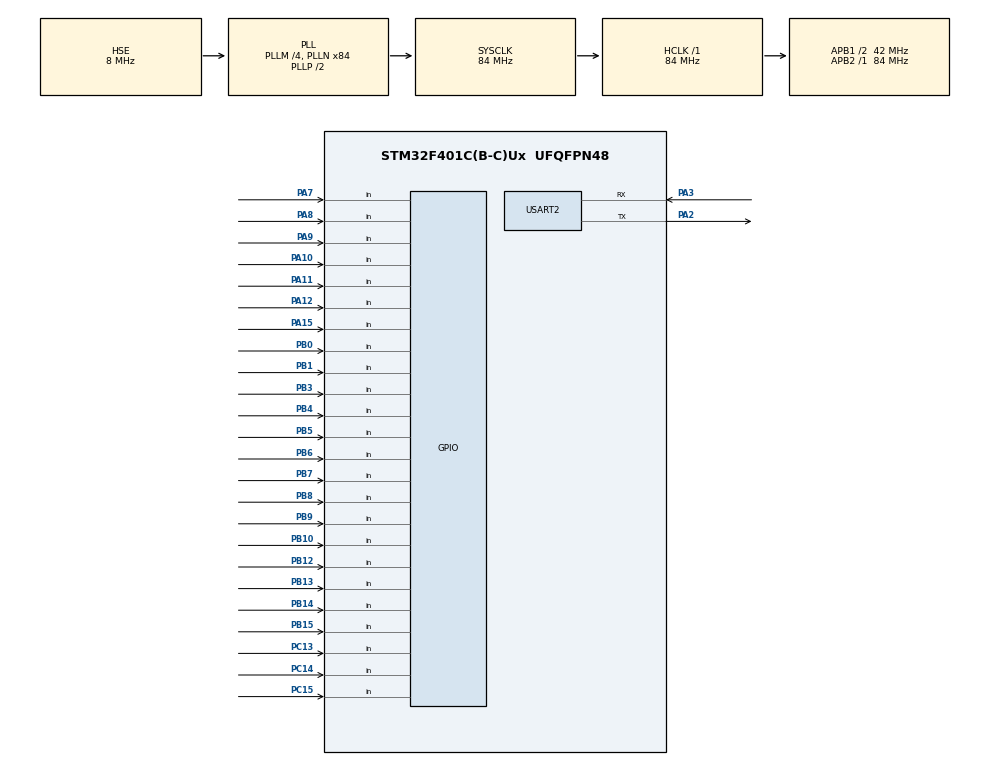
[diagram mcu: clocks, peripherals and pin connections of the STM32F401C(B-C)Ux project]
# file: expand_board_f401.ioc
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Mcu.Family=STM32F4
Mcu.Name=STM32F401C(B-C)Ux
Mcu.Package=UFQFPN48
NVIC.PriorityGroup=NVIC_PRIORITYGROUP_4
PA10.Signal=GPIO_Input
PA11.Signal=GPIO_Input
PA12.Signal=GPIO_Input
PA13.Mode=Serial_Wire
PA13.Signal=SYS_JTMS-SWDIO
PA14.Mode=Serial_Wire
PA14.Signal=SYS_JTCK-SWCLK
PA15.Signal=GPIO_Input
PA2.Mode=Asynchronous
PA2.Signal=USART2_TX
PA3.Mode=Asynchronous
PA3.Signal=USART2_RX
PA7.Signal=GPIO_Input
PA8.Signal=GPIO_Input
PA9.Signal=GPIO_Input
PB0.Signal=GPIO_Input
PB1.Signal=GPIO_Input
PB10.Signal=GPIO_Input
PB12.Signal=GPIO_Input
PB13.Signal=GPIO_Input
PB14.Signal=GPIO_Input
PB15.Signal=GPIO_Input
PB3.Signal=GPIO_Input
PB4.Signal=GPIO_Input
PB5.Signal=GPIO_Input
PB6.Signal=GPIO_Input
PB7.Signal=GPIO_Input
PB8.Signal=GPIO_Input
PB9.Signal=GPIO_Input
PC13-ANTI_TAMP.Signal=GPIO_Input
PC14-OSC32_IN.Signal=GPIO_Input
PC15-OSC32_OUT.Signal=GPIO_Input
PH0\ -\ OSC_IN.Mode=HSE-External-Oscillator
PH0\ -\ OSC_IN.Signal=RCC_OSC_IN
PH1\ -\ OSC_OUT.Mode=HSE-External-Oscillator
PH1\ -\ OSC_OUT.Signal=RCC_OSC_OUT
ProjectManager.HeapSize=0x200
ProjectManager.StackSize=0x400
ProjectManager.TargetToolchain=MDK-ARM V5.32
RCC.48MHZClocksFreq_Value=42000000
RCC.AHBFreq_Value=84000000
RCC.APB1CLKDivider=RCC_HCLK_DIV2
RCC.APB1Freq_Value=42000000
RCC.APB1TimFreq_Value=84000000
RCC.APB2Freq_Value=84000000
RCC.APB2TimFreq_Value=84000000
RCC.CortexFreq_Value=84000000
RCC.HCLKFreq_Value=84000000
RCC.HSE_VALUE=8000000
RCC.HSI_VALUE=16000000
RCC.LSE_VALUE=32768
RCC.PLLM=4
RCC.PLLN=84
RCC.PLLSourceVirtual=RCC_PLLSOURCE_HSE
RCC.SYSCLKFreq_VALUE=84000000
RCC.SYSCLKSource=RCC_SYSCLKSOURCE_PLLCLK
RCC.VCOOutputFreq_Value=168000000
USART2.VirtualMode=VM_ASYNC
board=custom

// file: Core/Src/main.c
/* USER CODE BEGIN Header */
/**
  ******************************************************************************
  * @file           : main.c
  * @brief          : Main program body
  ******************************************************************************
  * @attention
  *
  * <h2><center>&copy; Copyright (c) 2021 STMicroelectronics.
  * All rights reserved.</center></h2>
  *
  * This software component is licensed by ST under BSD 3-Clause license,
  * the "License"; You may not use this file except in compliance with the
  * License. You may obtain a copy of the License at:
  *                        opensource.org/licenses/BSD-3-Clause
  *
  ******************************************************************************
  */
/* USER CODE END Header */
#include "main.h"
#include "usart.h"
#include "gpio.h"

/* USER CODE BEGIN Includes */
#include "trackboard.h"
#include "usart_task.h"
/* USER CODE END Includes */

/* USER CODE BEGIN PV */
extern bool front_bar[9];
extern bool back_bar[9];
extern bool side_bar[9];
/* USER CODE END PV */

void SystemClock_Config(void);

int main(void)
{

  /* MCU Configuration--------------------------------------------------------*/

  /* Reset of all peripherals, Initializes the Flash interface and the Systick. */
  HAL_Init();

  /* Configure the system clock */
  SystemClock_Config();

  /* Initialize all configured peripherals */
  MX_GPIO_Init();
  MX_USART2_UART_Init();

  /* Infinite loop */
  while (1)
  {

    /* USER CODE BEGIN 3 */
    read_frontbar();
    read_backbar();
    read_sidebar();
    pack_bar_message(front_bar,back_bar,side_bar);
    send_tracking_message();
    printf("\r\n");
    HAL_Delay(10);
  }
  /* USER CODE END 3 */
}

void SystemClock_Config(void)
{
  RCC_OscInitTypeDef RCC_OscInitStruct = {0};
  RCC_ClkInitTypeDef RCC_ClkInitStruct = {0};

  /** Configure the main internal regulator output voltage
  */
  __HAL_RCC_PWR_CLK_ENABLE();
  __HAL_PWR_VOLTAGESCALING_CONFIG(PWR_REGULATOR_VOLTAGE_SCALE2);
  /** Initializes the RCC Oscillators according to the specified parameters
  * in the RCC_OscInitTypeDef structure.
  */
  RCC_OscInitStruct.OscillatorType = RCC_OSCILLATORTYPE_HSE;
  RCC_OscInitStruct.HSEState = RCC_HSE_ON;
  RCC_OscInitStruct.PLL.PLLState = RCC_PLL_ON;
  RCC_OscInitStruct.PLL.PLLSource = RCC_PLLSOURCE_HSE;
  RCC_OscInitStruct.PLL.PLLM = 4;
  RCC_OscInitStruct.PLL.PLLN = 84;
  RCC_OscInitStruct.PLL.PLLP = RCC_PLLP_DIV2;
  RCC_OscInitStruct.PLL.PLLQ = 4;
  if (HAL_RCC_OscConfig(&RCC_OscInitStruct) != HAL_OK)
  {
    Error_Handler();
  }
  /** Initializes the CPU, AHB and APB buses clocks
  */
  RCC_ClkInitStruct.ClockType = RCC_CLOCKTYPE_HCLK|RCC_CLOCKTYPE_SYSCLK
                              |RCC_CLOCKTYPE_PCLK1|RCC_CLOCKTYPE_PCLK2;
  RCC_ClkInitStruct.SYSCLKSource = RCC_SYSCLKSOURCE_PLLCLK;
  RCC_ClkInitStruct.AHBCLKDivider = RCC_SYSCLK_DIV1;
  RCC_ClkInitStruct.APB1CLKDivider = RCC_HCLK_DIV2;
  RCC_ClkInitStruct.APB2CLKDivider = RCC_HCLK_DIV1;

  if (HAL_RCC_ClockConfig(&RCC_ClkInitStruct, FLASH_LATENCY_2) != HAL_OK)
  {
    Error_Handler();
  }
}

void Error_Handler(void)
{
  __disable_irq();
  while (1)
  {
  }
}

/************************ (C) COPYRIGHT STMicroelectronics *****END OF FILE****/
